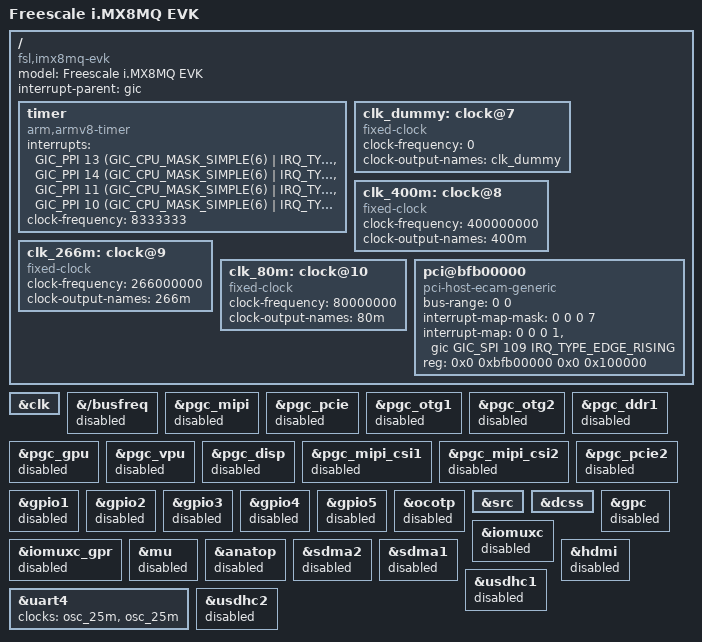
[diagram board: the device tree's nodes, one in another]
// SPDX-License-Identifier: (GPL-2.0+ OR MIT)
/*
 * Copyright 2019 NXP
 */

/dts-v1/;

#include "imx8mq.dtsi"

/ {
	model = "Freescale i.MX8MQ EVK";
	compatible = "fsl,imx8mq-evk", "fsl,imx8mq";
	interrupt-parent = <&gic>;

	timer {
		compatible = "arm,armv8-timer";
		interrupts = <GIC_PPI 13 (GIC_CPU_MASK_SIMPLE(6) | IRQ_TYPE_LEVEL_LOW)>, /* Physical Secure */
			     <GIC_PPI 14 (GIC_CPU_MASK_SIMPLE(6) | IRQ_TYPE_LEVEL_LOW)>, /* Physical Non-Secure */
			     <GIC_PPI 11 (GIC_CPU_MASK_SIMPLE(6) | IRQ_TYPE_LEVEL_LOW)>, /* Virtual */
			     <GIC_PPI 10 (GIC_CPU_MASK_SIMPLE(6) | IRQ_TYPE_LEVEL_LOW)>; /* Hypervisor */
		clock-frequency = <8333333>;
	};

	clk_dummy: clock@7 {
		compatible = "fixed-clock";
		#clock-cells = <0>;
		clock-frequency = <0>;
		clock-output-names = "clk_dummy";
	};

	/* The clocks are configured by 1st OS */
	clk_400m: clock@8 {
		compatible = "fixed-clock";
		#clock-cells = <0>;
		clock-frequency = <400000000>;
		clock-output-names = "400m";
	};
	clk_266m: clock@9 {
		compatible = "fixed-clock";
		#clock-cells = <0>;
		clock-frequency = <266000000>;
		clock-output-names = "266m";
	};
	clk_80m: clock@10 {
		compatible = "fixed-clock";
		#clock-cells = <0>;
		clock-frequency = <80000000>;
		clock-output-names = "80m";
	};

	pci@bfb00000 {
		compatible = "pci-host-ecam-generic";
		device_type = "pci";
		bus-range = <0 0>;
		#address-cells = <3>;
		#size-cells = <2>;
		#interrupt-cells = <1>;
		interrupt-map-mask = <0 0 0 7>;
		interrupt-map = <0 0 0 1 &gic GIC_SPI 109 IRQ_TYPE_EDGE_RISING>;
		reg = <0x0 0xbfb00000 0x0 0x100000>;
		ranges = <0x02000000 0x00 0x10000000 0x0 0x10000000 0x00 0x10000>;
	};
};

&clk {
	/delete-property/ compatible;
};

/delete-node/ &{/cpus/cpu@0};
/delete-node/ &{/cpus/cpu@1};
/delete-node/ &{/pmu};

&{/busfreq} {
	status = "disabled";
};

&pgc_mipi {
	status = "disabled";
};

&pgc_pcie {
	status = "disabled";
};

&pgc_otg1 {
	status = "disabled";
};

&pgc_otg2 {
	status = "disabled";
};

&pgc_ddr1 {
	status = "disabled";
};

&pgc_gpu {
	status = "disabled";
};

&pgc_vpu {
	status = "disabled";
};

&pgc_disp {
	status = "disabled";
};

&pgc_mipi_csi1 {
	status = "disabled";
};

&pgc_mipi_csi2 {
	status = "disabled";
};

&pgc_pcie2 {
	status = "disabled";
};

&gpio1 {
	status = "disabled";
};

&gpio2 {
	status = "disabled";
};

&gpio3 {
	status = "disabled";
};

&gpio4 {
	status = "disabled";
};

&gpio5 {
	status = "disabled";
};

/delete-node/ &tmu;
/delete-node/ &{/thermal-zones};

/delete-node/ &irqsteer;
&ocotp {
	/* not let imx8_soc_init hang system */
	/delete-property/ compatible;
	status = "disabled";
};
/delete-node/ &snvs;

&src {
	/delete-property/ compatible;
};

&dcss {
	/delete-property/ interrupt-parent;
	/delete-property/ interrupts;
	/delete-property/ interrupt-names;
};

&gpc {
	status = "disabled";
};

/delete-node/ &system_counter;
/*/delete-node/ &imx_ion;*/
/delete-node/ &pcie0;
/delete-node/ &pcie1;
/delete-node/ &vpu;
/delete-node/ &{/soc@0/ddr-pmu@3d800000};
/delete-node/ &rpmsg;
/delete-node/ &crypto;
/delete-node/ &caam_sm;
/delete-node/ &caam_snvs;
/delete-node/ &irq_sec_vio;
/delete-node/ &dma_apbh;
/delete-node/ &gpmi;

&iomuxc {
	status = "disabled";
};

&iomuxc_gpr {
	status = "disabled";
};

&mu {
	status = "disabled";
};

&anatop {
	status = "disabled";
};

&sdma2 {
	status = "disabled";
};

&sdma1 {
	status = "disabled";
};

&hdmi {
	status = "disabled";
};

&uart4 {
	clocks = <&osc_25m>,
		<&osc_25m>;
	clock-names = "ipg", "per";
	/delete-property/ dmas;
	/delete-property/ dmas-names;
	status = "okay";
};

// &uart1 {
// 	pinctrl-names = "default";
// 	pinctrl-0 = <&pinctrl_uart1>;
// 	assigned-clocks = <&clk IMX8MQ_CLK_UART1>;
// 	assigned-clock-parents = <&clk IMX8MQ_CLK_25M>;
// 	status = "okay";
// };
// uart1: serial@30860000 {
// 				compatible = "fsl,imx8mq-uart",
// 				             "fsl,imx6q-uart";
// 				reg = <0x30860000 0x10000>;
// 				interrupts = <GIC_SPI 26 IRQ_TYPE_LEVEL_HIGH>;
// 				clocks = <&clk IMX8MQ_CLK_UART1_ROOT>,
// 				         <&clk IMX8MQ_CLK_UART1_ROOT>;
// 				clock-names = "ipg", "per";
// 				status = "disabled";
// 			};
&usdhc1 {
	status = "disabled";
};

&usdhc2 {
	status = "disabled";
};

// 找到yocto中版本的gcc版本对应的gcc版本。
// &uart1 {
// 	/* uart2 is used by the 2nd OS, so configure pin and clk */
// 	pinctrl-0 = <&pinctrl_uart1>, <&pinctrl_uart2>;
// 	assigned-clocks = <&clk IMX8MQ_CLK_UART1>,
// 			<&clk IMX8MQ_CLK_UART2>;
// 	assigned-clock-parents = <&clk IMX8MQ_CLK_25M>,
// 			<&clk IMX8MQ_CLK_25M>;
// };

// &usdhc2 {
// 	clocks = <&clk_dummy>,
// 		<&clk_266m>,
// 		<&clk_400m>;
// 	/delete-property/assigned-clocks;
// 	/delete-property/assigned-clock-rates;
// 	clock-names = "ipg", "ahb", "per";
// 	bus-width = <8>;
// 	non-removable;
// 	status = "okay";
// };

// &usdhc2 {
// 	pinctrl-names = "default", "state_100mhz", "state_200mhz";
// 	pinctrl-0 = <&pinctrl_usdhc2>;
// 	pinctrl-1 = <&pinctrl_usdhc2_100mhz>;
// 	pinctrl-2 = <&pinctrl_usdhc2_200mhz>;
// 	cd-gpios = <&gpio2 12 GPIO_ACTIVE_LOW>;
// 	vmmc-supply = <&reg_usdhc2_vmmc>;
// 	status = "okay";
// };
